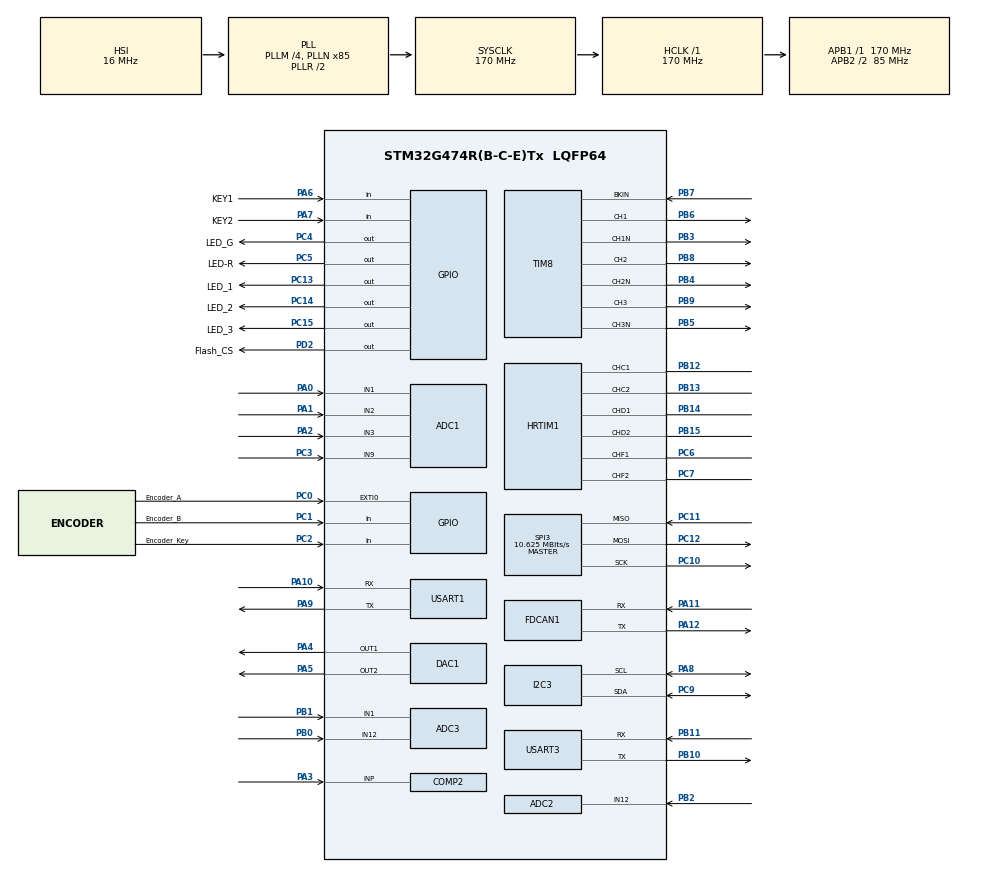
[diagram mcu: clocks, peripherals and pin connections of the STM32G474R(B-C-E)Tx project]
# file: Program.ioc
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ADC1.Channel-0\#ChannelRegularConversion=ADC_CHANNEL_1
ADC1.NbrOfConversionFlag=1
ADC1.OffsetNumber-0\#ChannelRegularConversion=ADC_OFFSET_NONE
ADC1.Rank-0\#ChannelRegularConversion=1
ADC1.SamplingTime-0\#ChannelRegularConversion=ADC_SAMPLETIME_2CYCLES_5
ADC1.SingleDiff-0\#ChannelRegularConversion=ADC_DIFFERENTIAL_ENDED
ADC1.master=1
ADC2.Channel-2\#ChannelRegularConversion=ADC_CHANNEL_12
ADC2.NbrOfConversionFlag=1
ADC2.OffsetNumber-2\#ChannelRegularConversion=ADC_OFFSET_NONE
ADC2.Rank-2\#ChannelRegularConversion=1
ADC2.SamplingTime-2\#ChannelRegularConversion=ADC_SAMPLETIME_2CYCLES_5
ADC3.Channel-2\#ChannelRegularConversion=ADC_CHANNEL_12
ADC3.NbrOfConversionFlag=1
ADC3.OffsetNumber-2\#ChannelRegularConversion=ADC_OFFSET_NONE
ADC3.Rank-2\#ChannelRegularConversion=1
ADC3.SamplingTime-2\#ChannelRegularConversion=ADC_SAMPLETIME_2CYCLES_5
ADC3.master=1
COMP2.Hysteresis=COMP_HYSTERESIS_20MV
DAC1.DAC_Channel-DAC_OUT2_ExtAndInt=DAC_CHANNEL_2
FDCAN1.CalculateBaudRateNominal=3541666
FDCAN1.CalculateTimeBitNominal=282
FDCAN1.CalculateTimeQuantumNominal=94.11764705882354
HRTIM1.Fault_Line1=__NULL
HRTIM1.Fault_Line3=__NULL
I2C3.Timing=0x40B285C2
Mcu.Family=STM32G4
Mcu.Name=STM32G474R(B-C-E)Tx
Mcu.Package=LQFP64
NVIC.PriorityGroup=NVIC_PRIORITYGROUP_4
PA0.Mode=IN1-Differential
PA0.Signal=ADC1_IN1
PA1.Mode=IN1-Differential
PA1.Signal=ADC1_IN2
PA10.Mode=Asynchronous
PA10.Signal=USART1_RX
PA11.Mode=FDCAN_Activate
PA11.Signal=FDCAN1_RX
PA12.Mode=FDCAN_Activate
PA12.Signal=FDCAN1_TX
PA13.Mode=Serial_Wire
PA13.Signal=SYS_JTMS-SWDIO
PA14.Mode=Serial_Wire
PA14.Signal=SYS_JTCK-SWCLK
PA2.Mode=IN3-Differential
PA2.Signal=ADC1_IN3
PA3.Signal=SharedAnalog_PA3
PA4.Signal=COMP_DAC11_group
PA5.Signal=COMP_DAC12_group
PA6.GPIO_Label=KEY1
PA6.Signal=GPIO_Input
PA7.GPIO_Label=KEY2
PA7.Signal=GPIO_Input
PA8.Mode=I2C
PA8.Signal=I2C3_SCL
PA9.Mode=Asynchronous
PA9.Signal=USART1_TX
PB0.Mode=IN12-Single-Ended
PB0.Signal=ADC3_IN12
PB1.Mode=IN1-Single-Ended
PB1.Signal=ADC3_IN1
PB10.Mode=Asynchronous
PB10.Signal=USART3_TX
PB11.Mode=Asynchronous
PB11.Signal=USART3_RX
PB12.Mode=Output_TC1TC2
PB12.Signal=HRTIM1_CHC1
PB13.Mode=Output_TC1TC2
PB13.Signal=HRTIM1_CHC2
PB14.Mode=Output_TD1TD2
PB14.Signal=HRTIM1_CHD1
PB15.Mode=Output_TD1TD2
PB15.Signal=HRTIM1_CHD2
PB2.Mode=IN12-Single-Ended
PB2.Signal=ADC2_IN12
PB3.Mode=PWM Generation1 CH1 CH1N
PB3.Signal=TIM8_CH1N
PB4.Mode=PWM Generation2 CH2 CH2N
PB4.Signal=TIM8_CH2N
PB5.Mode=PWM Generation3 CH3 CH3N
PB5.Signal=TIM8_CH3N
PB6.Signal=S_TIM8_CH1
PB7.Mode=Activate-Break-Input
PB7.Signal=TIM8_BKIN
PB8-BOOT0.Signal=S_TIM8_CH2
PB9.Signal=S_TIM8_CH3
PC0.GPIO_Label=Encoder_A
PC0.Signal=GPXTI0
PC1.GPIO_Label=Encoder_B
PC1.Signal=GPIO_Input
PC10.Mode=Full_Duplex_Master
PC10.Signal=SPI3_SCK
PC11.Mode=Full_Duplex_Master
PC11.Signal=SPI3_MISO
PC12.Mode=Full_Duplex_Master
PC12.Signal=SPI3_MOSI
PC13.GPIO_Label=LED_1
PC13.Signal=GPIO_Output
PC14-OSC32_IN.GPIO_Label=LED_2
PC14-OSC32_IN.Signal=GPIO_Output
PC15-OSC32_OUT.GPIO_Label=LED_3
PC15-OSC32_OUT.Signal=GPIO_Output
PC2.GPIO_Label=Encoder_Key
PC2.Signal=GPIO_Input
PC3.Mode=IN9-Single-Ended
PC3.Signal=ADC1_IN9
PC4.GPIO_Label=LED_G
PC4.Signal=GPIO_Output
PC5.GPIO_Label=LED-R
PC5.Signal=GPIO_Output
PC6.Mode=Output_TF1TF2
PC6.Signal=HRTIM1_CHF1
PC7.Mode=Output_TF1TF2
PC7.Signal=HRTIM1_CHF2
PC9.Mode=I2C
PC9.Signal=I2C3_SDA
PD2.GPIO_Label=Flash_CS
PD2.Signal=GPIO_Output
PF0-OSC_IN.Mode=HSE-External-Oscillator
PF0-OSC_IN.Signal=RCC_OSC_IN
PF1-OSC_OUT.Mode=HSE-External-Oscillator
PF1-OSC_OUT.Signal=RCC_OSC_OUT
ProjectManager.HeapSize=0x200
ProjectManager.StackSize=0x400
ProjectManager.TargetToolchain=CMake
RCC.ADC12Freq_Value=170000000
RCC.ADC345Freq_Value=170000000
RCC.AHBFreq_Value=170000000
RCC.APB1Freq_Value=170000000
RCC.APB1TimFreq_Value=170000000
RCC.APB2CLKDivider=RCC_HCLK_DIV2
RCC.APB2Freq_Value=85000000
RCC.APB2TimFreq_Value=170000000
RCC.CortexFreq_Value=170000000
RCC.EXTERNAL_CLOCK_VALUE=12288000
RCC.HCLKFreq_Value=170000000
RCC.HSE_VALUE=8000000
RCC.HSI48_VALUE=48000000
RCC.HSI_VALUE=16000000
RCC.LSE_VALUE=32768
RCC.PLLM=RCC_PLLM_DIV4
RCC.PLLN=85
RCC.SYSCLKFreq_VALUE=170000000
RCC.SYSCLKSource=RCC_SYSCLKSOURCE_PLLCLK
RCC.USBFreq_Value=170000000
RCC.VCOOutputFreq_Value=340000000
SH.COMP_DAC11_group.0=DAC1_OUT1,DAC_OUT1
SH.COMP_DAC12_group.0=DAC1_OUT2,DAC_OUT2_ExtAndInt
SH.S_TIM8_CH1.0=TIM8_CH1,PWM Generation1 CH1 CH1N
SH.S_TIM8_CH2.0=TIM8_CH2,PWM Generation2 CH2 CH2N
SH.S_TIM8_CH3.0=TIM8_CH3,PWM Generation3 CH3 CH3N
SH.SharedAnalog_PA3.0=COMP2_INP,INP
SH.SharedAnalog_PA3.1=ADC1_IN4,IN3-Differential
SPI3.BaudRatePrescaler=SPI_BAUDRATEPRESCALER_16
SPI3.CLKPolarity=SPI_POLARITY_HIGH
SPI3.CalculateBaudRate=10.625 MBits/s
SPI3.Direction=SPI_DIRECTION_2LINES
SPI3.Mode=SPI_MODE_MASTER
SPI3.VirtualNSS=VM_NSSHARD
SPI3.VirtualType=VM_MASTER
TIM8.AutomaticOutput=TIM_AUTOMATICOUTPUT_ENABLE
TIM8.BreakAFMode=TIM_BREAK_AFMODE_INPUT
TIM8.BreakFilter=1
TIM8.Channel-PWM\ Generation1\ CH1\ CH1N=TIM_CHANNEL_1
TIM8.Channel-PWM\ Generation2\ CH2\ CH2N=TIM_CHANNEL_2
TIM8.Channel-PWM\ Generation3\ CH3\ CH3N=TIM_CHANNEL_3
TIM8.DeadTime=100
TIM8.DeadTimePreload=DISABLE
TIM8.SourceBRKCOMP2=TIM_BREAKINPUTSOURCE_ENABLE
USART1.VirtualMode-Asynchronous=VM_ASYNC
USART3.VirtualMode-Asynchronous=VM_ASYNC
VP_COMP2_VS_DAC1OUT2.Mode=INM_DAC1OUT2
VP_HRTIM1_VS_hrtimMasterTimerNoOutput.Mode=MasterTimer
VP_SYS_VS_DBSignals.Mode=DisableDeadBatterySignals
board=custom

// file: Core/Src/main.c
/* USER CODE BEGIN Header */
/**
  ******************************************************************************
  * @file           : main.c
  * @brief          : Main program body
  ******************************************************************************
  * @attention
  *
  * Copyright (c) 2026 STMicroelectronics.
  * All rights reserved.
  *
  * This software is licensed under terms that can be found in the LICENSE file
  * in the root directory of this software component.
  * If no LICENSE file comes with this software, it is provided AS-IS.
  *
  ******************************************************************************
  */
/* USER CODE END Header */
#include "main.h"
#include "adc.h"
#include "comp.h"
#include "dac.h"
#include "fdcan.h"
#include "hrtim.h"
#include "i2c.h"
#include "spi.h"
#include "tim.h"
#include "usart.h"
#include "gpio.h"

/* USER CODE BEGIN Includes */
#include "demo_app.h"
#include "encoder.h"
#include "jdy31.h"

/* USER CODE END Includes */

void SystemClock_Config(void);

int main(void)
{

  /* MCU Configuration--------------------------------------------------------*/

  /* Reset of all peripherals, Initializes the Flash interface and the Systick. */
  HAL_Init();

  /* Configure the system clock */
  SystemClock_Config();

  /* Initialize all configured peripherals */
  MX_GPIO_Init();
  MX_DAC1_Init();
  MX_FDCAN1_Init();
  MX_USART1_UART_Init();
  MX_ADC1_Init();
  MX_ADC2_Init();
  MX_ADC3_Init();
  MX_HRTIM1_Init();
  MX_I2C3_Init();
  MX_SPI3_Init();
  MX_TIM8_Init();
  MX_USART3_UART_Init();
  MX_COMP2_Init();
  /* USER CODE BEGIN 2 */
  DemoApp_Init();
  /* USER CODE END 2 */

  /* Infinite loop */
  while (1)
  {

    /* USER CODE BEGIN 3 */
    DemoApp_Run();
  }
  /* USER CODE END 3 */
}

void SystemClock_Config(void)
{
  RCC_OscInitTypeDef RCC_OscInitStruct = {0};
  RCC_ClkInitTypeDef RCC_ClkInitStruct = {0};

  /** Configure the main internal regulator output voltage
  */
  HAL_PWREx_ControlVoltageScaling(PWR_REGULATOR_VOLTAGE_SCALE1_BOOST);

  /** Initializes the RCC Oscillators according to the specified parameters
  * in the RCC_OscInitTypeDef structure.
  */
  RCC_OscInitStruct.OscillatorType = RCC_OSCILLATORTYPE_HSI;
  RCC_OscInitStruct.HSIState = RCC_HSI_ON;
  RCC_OscInitStruct.HSICalibrationValue = RCC_HSICALIBRATION_DEFAULT;
  RCC_OscInitStruct.PLL.PLLState = RCC_PLL_ON;
  RCC_OscInitStruct.PLL.PLLSource = RCC_PLLSOURCE_HSI;
  RCC_OscInitStruct.PLL.PLLM = RCC_PLLM_DIV4;
  RCC_OscInitStruct.PLL.PLLN = 85;
  RCC_OscInitStruct.PLL.PLLP = RCC_PLLP_DIV2;
  RCC_OscInitStruct.PLL.PLLQ = RCC_PLLQ_DIV2;
  RCC_OscInitStruct.PLL.PLLR = RCC_PLLR_DIV2;
  if (HAL_RCC_OscConfig(&RCC_OscInitStruct) != HAL_OK)
  {
    Error_Handler();
  }

  /** Initializes the CPU, AHB and APB buses clocks
  */
  RCC_ClkInitStruct.ClockType = RCC_CLOCKTYPE_HCLK|RCC_CLOCKTYPE_SYSCLK
                              |RCC_CLOCKTYPE_PCLK1|RCC_CLOCKTYPE_PCLK2;
  RCC_ClkInitStruct.SYSCLKSource = RCC_SYSCLKSOURCE_PLLCLK;
  RCC_ClkInitStruct.AHBCLKDivider = RCC_SYSCLK_DIV1;
  RCC_ClkInitStruct.APB1CLKDivider = RCC_HCLK_DIV1;
  RCC_ClkInitStruct.APB2CLKDivider = RCC_HCLK_DIV2;

  if (HAL_RCC_ClockConfig(&RCC_ClkInitStruct, FLASH_LATENCY_4) != HAL_OK)
  {
    Error_Handler();
  }
}

/* USER CODE BEGIN 4 */
void HAL_GPIO_EXTI_Callback(uint16_t GPIO_Pin)
{
  Encoder_HandleExti(GPIO_Pin);
}

void HAL_UART_RxCpltCallback(UART_HandleTypeDef *huart)
{
  JDY31_RxCpltCallback(huart);
}

void HAL_UART_ErrorCallback(UART_HandleTypeDef *huart)
{
  JDY31_ErrorCallback(huart);
}
/* USER CODE END 4 */

void Error_Handler(void)
{
  __disable_irq();
  while (1)
  {
  }
}
